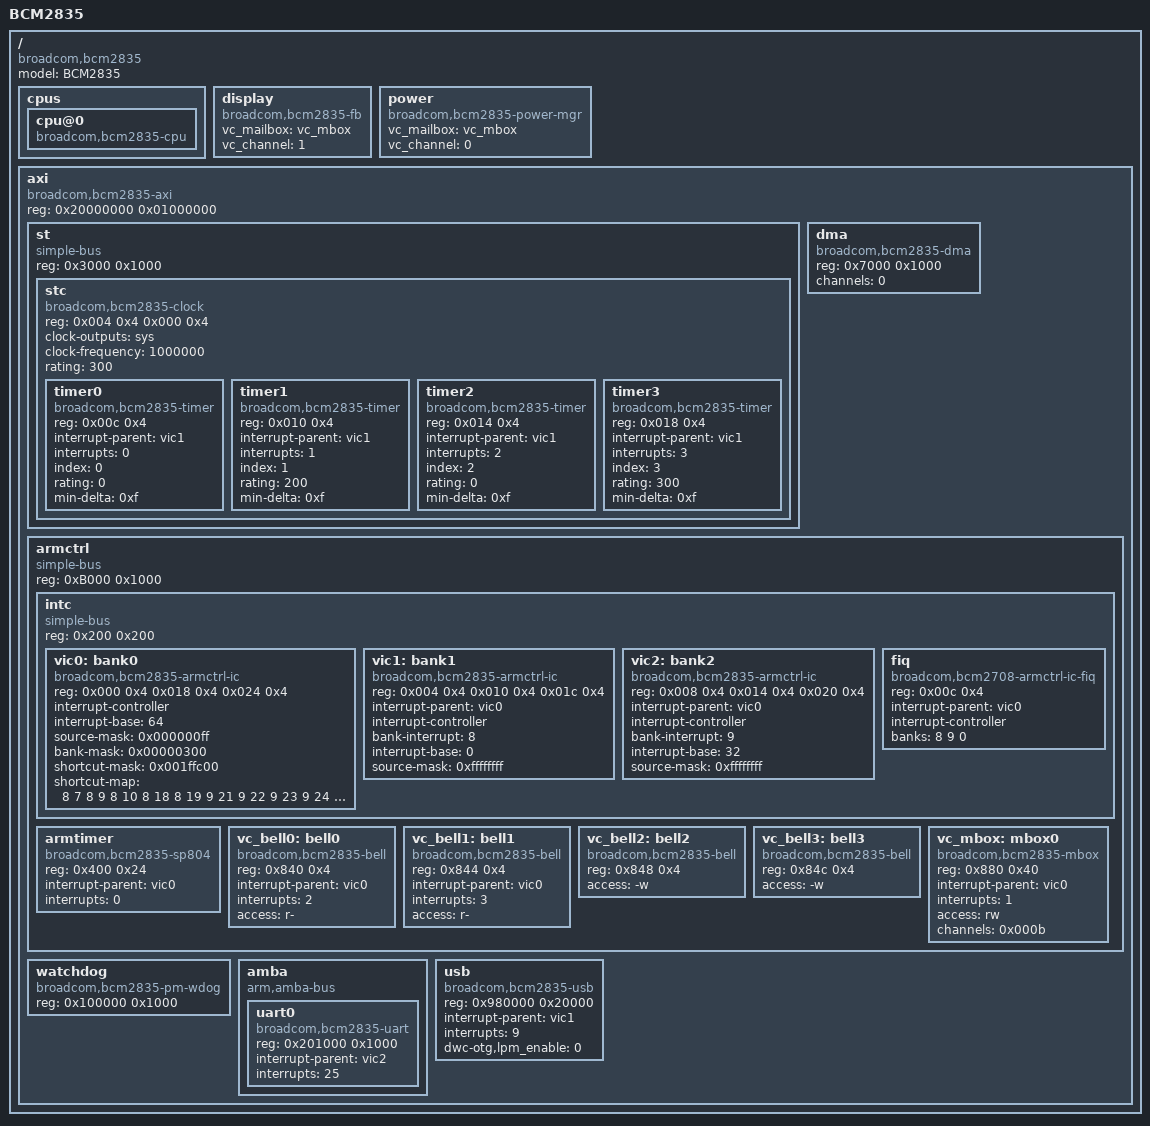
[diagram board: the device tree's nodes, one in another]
/dts-v1/;
/include/ "skeleton.dtsi"

/ {
	model = "BCM2835";
	#address-cells = <1>;
	#size-cells = <1>;
	compatible = "broadcom,bcm2835", "broadcom,bcm2708";

	cpus {
		cpu@0 {
			compatible = "broadcom,bcm2835-cpu", "broadcom,bcm2708-cpu", "arm,1176jz-f";
		};
	};

	display {
		compatible = "broadcom,bcm2835-fb", "broadcom,bcm2708-fb";
		#address-cells = <0>;
		#size-cells = <0>;

		vc_mailbox = <&vc_mbox>;
		vc_channel = <1>;
	};

	power {
		compatible = "broadcom,bcm2835-power-mgr", "broadcom,bcm2708-power-mgr";
		#address-cells = <0>;
		#size-cells = <0>;

		vc_mailbox = <&vc_mbox>;
		vc_channel = <0>;
	};

	axi {
		compatible = "broadcom,bcm2835-axi", "broadcom,bcm2708-axi", "simple-bus";
		#address-cells = <1>;
		#size-cells = <1>;
		reg = <0x20000000 0x01000000>;
		ranges = <0 0x20000000 0x01000000>;

		st {
			compatible = "simple-bus";
			#address-cells = <1>;
			#size-cells = <1>;
			reg = <0x3000 0x1000>;
			ranges = <0 0x3000 0x1000>;

			stc {
				compatible = "broadcom,bcm2835-clock", "broadcom,bcm2708-clock", "mmio-clock", "simple-bus";
				#address-cells = <1>;
				#size-cells = <1>;
				reg = <0x004 0x4 0x000 0x4>;
				reg-names = "counter", "control";
				ranges;

				clock-outputs = "sys";
				clock-frequency = <1000000>;
				rating = <300>;

				/* DO NOT USE (it doesn't work) */
				timer0 {
					compatible = "broadcom,bcm2835-timer", "broadcom,bcm2708-clock", "mmio-timer";
					reg = <0x00c 0x4>;
					reg-names = "compare";
					interrupt-parent = <&vic1>;
					interrupts = <0>;

					index = <0>;
					rating = <0>;
					min-delta = <0xf>;
				};

				/* Usable system timer */
				timer1 {
					compatible = "broadcom,bcm2835-timer", "broadcom,bcm2708-clock", "mmio-timer";
					reg = <0x010 0x4>;
					reg-names = "compare";
					interrupt-parent = <&vic1>;
					interrupts = <1>;

					index = <1>;
					rating = <200>;
					min-delta = <0xf>;
				};

				/* DO NOT USE (generates extra interrupts) */
				timer2 {
					compatible = "broadcom,bcm2835-timer", "broadcom,bcm2708-clock", "mmio-timer";
					reg = <0x014 0x4>;
					reg-names = "compare";
					interrupt-parent = <&vic1>;
					interrupts = <2>;

					index = <2>;
					rating = <0>;
					min-delta = <0xf>;
				};

				/* Usable system timer */
				timer3 {
					compatible = "broadcom,bcm2835-timer", "broadcom,bcm2708-clock", "mmio-timer";
					reg = <0x018 0x4>;
					reg-names = "compare";
					interrupt-parent = <&vic1>;
					interrupts = <3>;

					index = <3>;
					rating = <300>;
					min-delta = <0xf>;
				};
			};
		};

		dma {
			compatible = "broadcom,bcm2835-dma", "broadcom,bcm2708-dma";
			reg = <0x7000 0x1000>;

			channels = <0>;
		};

		armctrl {
			compatible = "simple-bus";
			#address-cells = <1>;
			#size-cells = <1>;
			reg = <0xB000 0x1000>;
			ranges = <0 0xB000 0x1000>;

			intc {
				compatible = "simple-bus";
				#address-cells = <1>;
				#size-cells = <1>;
				reg = <0x200 0x200>;
				ranges = <0 0x200 0x200>;

				vic0: bank0 {
					compatible = "broadcom,bcm2835-armctrl-ic", "broadcom,bcm2708-armctrl-ic";
					reg = <0x000 0x4 0x018 0x4 0x024 0x4>;
					reg-names = "pending", "enable", "disable";
					interrupt-controller;
					#interrupt-cells = <1>;

					interrupt-base = <64>;

					/* IRQs
					 * 0: ARM_TIMER
					 * 1: ARM_MAILBOX
					 * 2: ARM_DOORBELL_0
					 * 3: ARM_DOORBELL_1
					 * 4: VPU0_HALTED
					 * 5: VPU1_HALTED
					 * 6: ILLEGAL_TYPE0
					 * 7: ILLEGAL_TYPE1
					 */
					source-mask = <0x000000ff>;

					/* Banks
					 * 8: PENDING1
					 * 9: PENDING2
					 */
					bank-mask = <0x00000300>;

					/* Shortcuts */
					shortcut-mask = <0x001ffc00>;
					shortcut-map = <
						8  7	/* 10: VC_JPEG */
						8  9	/* 11: VC_USB */
						8 10	/* 12: VC_3D */
						8 18	/* 13: VC_DMA2 */
						8 19	/* 14: VC_DMA3 */
						9 21	/* 15: VC_I2C */
						9 22	/* 16: VC_SPI */
						9 23	/* 17: VC_I2SPCM */
						9 24	/* 18: VC_SDIO */
						9 25	/* 19: VC_UART */
						9 30	/* 20: VC_ARASANSDIO */
					>;
				};

				vic1: bank1 {
					compatible = "broadcom,bcm2835-armctrl-ic", "broadcom,bcm2708-armctrl-ic";
					reg = <0x004 0x4 0x010 0x4 0x01c 0x4>;
					reg-names = "pending", "enable", "disable";
					interrupt-parent = <&vic0>;
					interrupt-controller;
					#interrupt-cells = <1>;
					#address-cells = <0>;

					bank-interrupt = <8>;
					interrupt-base = <0>;

					/* IRQs
					 * 0: TIMER0		16: DMA0
					 * 1: TIMER1		17: DMA1
					 * 2: TIMER2		18: VC_DMA2
					 * 3: TIMER3		19: VC_DMA3
					 * 4: CODEC0		20: DMA4
					 * 5: CODEC1		21: DMA5
					 * 6: CODEC2		22: DMA6
					 * 7: VC_JPEG		23: DMA7
					 * 8: ISP		24: DMA8
					 * 9: VC_USB		25: DMA9
					 * 10: VC_3D		26: DMA10
					 * 11: TRANSPOSER	27: DMA11
					 * 12: MULTICORESYNC0	28: DMA12
					 * 13: MULTICORESYNC1	29: AUX
					 * 14: MULTICORESYNC2	30: ARM
					 * 15: MULTICORESYNC3	31: VPUDMA
					 */
					source-mask = <0xffffffff>;
				};

				vic2: bank2 {
					compatible = "broadcom,bcm2835-armctrl-ic", "broadcom,bcm2708-armctrl-ic";
					reg = <0x008 0x4 0x014 0x4 0x020 0x4>;
					reg-names = "pending", "enable", "disable";
					interrupt-parent = <&vic0>;
					interrupt-controller;
					#interrupt-cells = <1>;
					#address-cells = <0>;

					bank-interrupt = <9>;
					interrupt-base = <32>;

					/* IRQs
					 * 0: HOSTPORT		16: SMI
					 * 1: VIDEOSCALER	17: GPIO0
					 * 2: CCP2TX		18: GPIO1
					 * 3: SDC		19: GPIO2
					 * 4: DSI0		20: GPIO3
					 * 5: AVE		21: VC_I2C
					 * 6: CAM0		22: VC_SPI
					 * 7: CAM1		23: VC_I2SPCM
					 * 8: HDMI0		24: VC_SDIO
					 * 9: HDMI1		25: VC_UART
					 * 10: PIXELVALVE1	26: SLIMBUS
					 * 11: I2CSPISLV	27: VEC
					 * 12: DSI1		28: CPG
					 * 13: PWA0		29: RNG
					 * 14: PWA1		30: VC_ARASANSDIO
					 * 15: CPR		31: AVSPMON
					 */
					source-mask = <0xffffffff>;
				};

				fiq {
					compatible = "broadcom,bcm2708-armctrl-ic-fiq", "broadcom,bcm2835-armctrl-ic-fiq";
					/* Bits 0-6: IRQ (index in order of banks below)
					 * Bit    7: Enable FIQ generation
					 * Bits  8+: Unused
					 *
					 * An interrupt must be disabled before
					 * configuring it for FIQ generation
					 * otherwise both handlers will fire at
					 * the same time!
					 */
					reg = <0x00c 0x4>;
					reg-names = "control";
					interrupt-parent = <&vic0>;
					interrupt-controller;
					#interrupt-cells = <0>;

					banks = <8 9 0>;
				};
			};

			armtimer {
				/* Not AMBA compatible */
				compatible = "broadcom,bcm2835-sp804", "arm,sp804";
				reg = <0x400 0x24>;

				interrupt-parent = <&vic0>;
				interrupts = <0>;
			};

			vc_bell0: bell0 {
				compatible = "broadcom,bcm2835-bell", "broadcom,bcm2708-bell";
				reg = <0x840 0x4>;
				interrupt-parent = <&vic0>;
				interrupts = <2>;

				access = "r-";
			};

			vc_bell1: bell1 {
				compatible = "broadcom,bcm2835-bell", "broadcom,bcm2708-bell";
				reg = <0x844 0x4>;
				interrupt-parent = <&vic0>;
				interrupts = <3>;

				access = "r-";
			};

			vc_bell2: bell2 {
				compatible = "broadcom,bcm2835-bell", "broadcom,bcm2708-bell";
				reg = <0x848 0x4>;

				access = "-w";
			};

			vc_bell3: bell3 {
				compatible = "broadcom,bcm2835-bell", "broadcom,bcm2708-bell";
				reg = <0x84c 0x4>;

				access = "-w";
			};

			vc_mbox: mbox0 {
				compatible = "broadcom,bcm2835-mbox", "broadcom,bcm2708-mbox";
				reg = <0x880 0x40>;
				interrupt-parent = <&vic0>;
				interrupts = <1>;

				/* Read from 0x00..0x1f, Write to 0x20..3f */
				access = "rw";

				/* Channels
				 * 0: power
				 * 1: fb
				 * 3: vchiq
				 */
				channels = <0x000b>;
			};
		};

		watchdog {
			compatible = "broadcom,bcm2835-pm-wdog", "broadcom,bcm2708-pm-wdog";
			reg = <0x100000 0x1000>;
		};

		amba {
			compatible = "arm,amba-bus";
			#address-cells = <1>;
			#size-cells = <1>;
			ranges;

			uart0 {
				compatible = "broadcom,bcm2835-uart", "broadcom,bcm2708-uart", "arm,pl011", "arm,primecell";
				reg = <0x201000 0x1000>;
				interrupt-parent = <&vic2>;
				interrupts = <25>;
			};
		};

		/* Auxiliary device disabled by default */
		/*
		uart1 {
			compatible = "broadcom,bcm2835-miniuart", "broadcom,bcm2708-miniuart", "ns16550";
			reg = <0x215040 0x38>;
			interrupt-parent = <&vic1>;
			interrupts = <29>;
		};
		*/

		usb {
			compatible = "broadcom,bcm2835-usb", "broadcom,bcm2708-usb", "synopsys,designware-hs-otg";
			reg = <0x980000 0x20000>;
			interrupt-parent = <&vic1>;
			interrupts = <9>;

			dwc-otg,lpm_enable = <0>;
		};
	};
};
